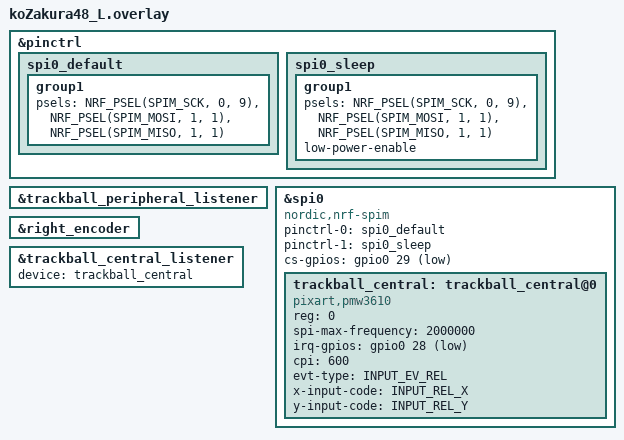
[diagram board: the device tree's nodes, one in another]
#include "koZakura48.dtsi"
#include <input/processors.dtsi>

//追加文
&pinctrl {
    spi0_default: spi0_default {    //通常時(SPI通信中)のピン構成
        group1 {
            psels = <NRF_PSEL(SPIM_SCK, 0, 9)>, //P0.05を指定(SCLK)
                <NRF_PSEL(SPIM_MOSI, 1, 1)>,    //P0.04を指定(SDIOだからMOSI,MISO両方の役割を担う)
                <NRF_PSEL(SPIM_MISO, 1, 1)>;
        };
    };

    spi0_sleep: spi0_sleep {    //スリープ時のピン構成(省電力)
        group1 {
            psels = <NRF_PSEL(SPIM_SCK, 0, 9)>,
                <NRF_PSEL(SPIM_MOSI, 1, 1)>,
                <NRF_PSEL(SPIM_MISO, 1, 1)>;
            low-power-enable;
        };
    };
};

&trackball_peripheral_listener {
    status = "okay";
};

#include <zephyr/dt-bindings/input/input-event-codes.h>
&spi0 {
    status = "okay";
    compatible = "nordic,nrf-spim"; //マイコンがnRFシリーズ
    pinctrl-0 = <&spi0_default>;
    pinctrl-1 = <&spi0_sleep>;
    pinctrl-names = "default", "sleep";
    cs-gpios = <&gpio0 29 GPIO_ACTIVE_LOW>;  //P0.29を指定(CS)

    trackball_central: trackball_central@0 {
        status = "okay";
        compatible = "pixart,pmw3610";  //トラボセンサ用のドライバとバインド
        reg = <0>;
        spi-max-frequency = <2000000>;
        irq-gpios = <&gpio0 28 (GPIO_ACTIVE_LOW | GPIO_PULL_UP)>; //P0.28を指定(MOTION)
        cpi = <600>; //gptにきいてコメントアウト（conf内にcpiの記載あり）
        evt-type = <INPUT_EV_REL>;
        x-input-code = <INPUT_REL_X>;
        y-input-code = <INPUT_REL_Y>;
    };
};

&right_encoder {
    status = "okay";
}; //gptにきいて;を足しました

// Overrides for the input listener node
&trackball_central_listener {
    status = "okay";
    device = <&trackball_central>;
};


